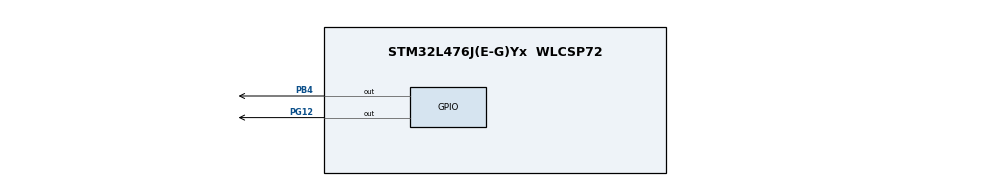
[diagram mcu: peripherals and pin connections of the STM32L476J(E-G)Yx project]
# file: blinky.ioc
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Mcu.Family=STM32L4
Mcu.Name=STM32L476J(E-G)Yx
Mcu.Package=WLCSP72
NVIC.PriorityGroup=NVIC_PRIORITYGROUP_4
PB4\ (NJTRST).Signal=GPIO_Output
PG12.Signal=GPIO_Output
ProjectManager.HeapSize=0x200
ProjectManager.StackSize=0x400
ProjectManager.TargetToolchain=SW4STM32
RCC.HSE_VALUE=8000000
RCC.HSI_VALUE=16000000
RCC.LSE_VALUE=32768
RCC.MSI_VALUE=4000000
RCC.VCOOutputFreq_Value=32000000
board=custom

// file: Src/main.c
/* USER CODE BEGIN Header */
/**
 ******************************************************************************
 * @file           : main.c
 * @brief          : Main program body
 ******************************************************************************
 * @attention
 *
 * <h2><center>&copy; Copyright (c) 2020 STMicroelectronics.
 * All rights reserved.</center></h2>
 *
 * This software component is licensed by ST under BSD 3-Clause license,
 * the "License"; You may not use this file except in compliance with the
 * License. You may obtain a copy of the License at:
 *                        opensource.org/licenses/BSD-3-Clause
 *
 ******************************************************************************
 */
/* USER CODE END Header */

#include "main.h"

void SystemClock_Config(void);
static void MX_GPIO_Init(void);

int main(void) {

    /* MCU Configuration--------------------------------------------------------*/

    /* Reset of all peripherals, Initializes the Flash interface and the Systick. */
    HAL_Init();

    /* Configure the system clock */
    SystemClock_Config();

    /* Initialize all configured peripherals */
    MX_GPIO_Init();

    /* Infinite loop */
    while (1) {

        /* USER CODE BEGIN 3 */
        HAL_GPIO_TogglePin(GPIOG, GPIO_PIN_12);
        HAL_Delay(500);
    }
    /* USER CODE END 3 */
}

void SystemClock_Config(void) {
    RCC_OscInitTypeDef RCC_OscInitStruct = { 0 };
    RCC_ClkInitTypeDef RCC_ClkInitStruct = { 0 };

    /** Initializes the CPU, AHB and APB busses clocks
     */
    RCC_OscInitStruct.OscillatorType = RCC_OSCILLATORTYPE_MSI;
    RCC_OscInitStruct.MSIState = RCC_MSI_ON;
    RCC_OscInitStruct.MSICalibrationValue = 0;
    RCC_OscInitStruct.MSIClockRange = RCC_MSIRANGE_6;
    RCC_OscInitStruct.PLL.PLLState = RCC_PLL_NONE;
    if (HAL_RCC_OscConfig(&RCC_OscInitStruct) != HAL_OK) {
        Error_Handler();
    }
    /** Initializes the CPU, AHB and APB busses clocks
     */
    RCC_ClkInitStruct.ClockType = RCC_CLOCKTYPE_HCLK | RCC_CLOCKTYPE_SYSCLK
            | RCC_CLOCKTYPE_PCLK1 | RCC_CLOCKTYPE_PCLK2;
    RCC_ClkInitStruct.SYSCLKSource = RCC_SYSCLKSOURCE_MSI;
    RCC_ClkInitStruct.AHBCLKDivider = RCC_SYSCLK_DIV1;
    RCC_ClkInitStruct.APB1CLKDivider = RCC_HCLK_DIV1;
    RCC_ClkInitStruct.APB2CLKDivider = RCC_HCLK_DIV1;

    if (HAL_RCC_ClockConfig(&RCC_ClkInitStruct, FLASH_LATENCY_0) != HAL_OK) {
        Error_Handler();
    }
    /** Configure the main internal regulator output voltage
     */
    if (HAL_PWREx_ControlVoltageScaling(PWR_REGULATOR_VOLTAGE_SCALE1)
            != HAL_OK) {
        Error_Handler();
    }
}

static void MX_GPIO_Init(void) {
    GPIO_InitTypeDef GPIO_InitStruct = { 0 };

    /* GPIO Ports Clock Enable */
    __HAL_RCC_GPIOG_CLK_ENABLE()
    ;
    HAL_PWREx_EnableVddIO2();

    /*Configure GPIO pin Output Level */
    HAL_GPIO_WritePin(GPIOG, GPIO_PIN_12, GPIO_PIN_RESET);

    /*Configure GPIO pin : PG12 */
    GPIO_InitStruct.Pin = GPIO_PIN_12;
    GPIO_InitStruct.Mode = GPIO_MODE_OUTPUT_PP;
    GPIO_InitStruct.Pull = GPIO_NOPULL;
    GPIO_InitStruct.Speed = GPIO_SPEED_FREQ_LOW;
    HAL_GPIO_Init(GPIOG, &GPIO_InitStruct);

}

void Error_Handler(void) {
}

/************************ (C) COPYRIGHT STMicroelectronics *****END OF FILE****/
